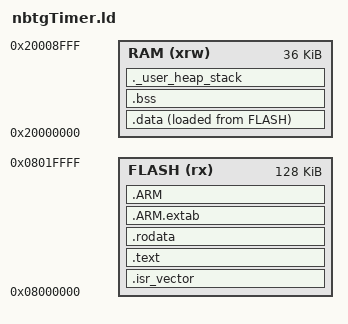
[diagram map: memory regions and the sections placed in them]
/*
******************************************************************************
**

**  File        : LinkerScript.ld
**
**  Author		: STM32CubeMX
**
**  Abstract    : Linker script for STM32G070RBTx series
**                128Kbytes FLASH and 36Kbytes RAM
**
**                Set heap size, stack size and stack location according
**                to application requirements.
**
**                Set memory bank area and size if external memory is used.
**
**  Target      : STMicroelectronics STM32
**
**  Distribution: The file is distributed “as is,” without any warranty
**                of any kind.
**
*****************************************************************************
** @attention
**
** <h2><center>&copy; COPYRIGHT(c) 2019 STMicroelectronics</center></h2>
**
** Redistribution and use in source and binary forms, with or without modification,
** are permitted provided that the following conditions are met:
**   1. Redistributions of source code must retain the above copyright notice,
**      this list of conditions and the following disclaimer.
**   2. Redistributions in binary form must reproduce the above copyright notice,
**      this list of conditions and the following disclaimer in the documentation
**      and/or other materials provided with the distribution.
**   3. Neither the name of STMicroelectronics nor the names of its contributors
**      may be used to endorse or promote products derived from this software
**      without specific prior written permission.
**
** THIS SOFTWARE IS PROVIDED BY THE COPYRIGHT HOLDERS AND CONTRIBUTORS "AS IS"
** AND ANY EXPRESS OR IMPLIED WARRANTIES, INCLUDING, BUT NOT LIMITED TO, THE
** IMPLIED WARRANTIES OF MERCHANTABILITY AND FITNESS FOR A PARTICULAR PURPOSE ARE
** DISCLAIMED. IN NO EVENT SHALL THE COPYRIGHT HOLDER OR CONTRIBUTORS BE LIABLE
** FOR ANY DIRECT, INDIRECT, INCIDENTAL, SPECIAL, EXEMPLARY, OR CONSEQUENTIAL
** DAMAGES (INCLUDING, BUT NOT LIMITED TO, PROCUREMENT OF SUBSTITUTE GOODS OR
** SERVICES; LOSS OF USE, DATA, OR PROFITS; OR BUSINESS INTERRUPTION) HOWEVER
** CAUSED AND ON ANY THEORY OF LIABILITY, WHETHER IN CONTRACT, STRICT LIABILITY,
** OR TORT (INCLUDING NEGLIGENCE OR OTHERWISE) ARISING IN ANY WAY OUT OF THE USE
** OF THIS SOFTWARE, EVEN IF ADVISED OF THE POSSIBILITY OF SUCH DAMAGE.
**
*****************************************************************************
*/

ENTRY(Reset_Handler)

_estack = ORIGIN(RAM) + LENGTH(RAM);    /* end of RAM */

_Min_Heap_Size  = 0x0;
_Min_Stack_Size = 0x400;

MEMORY
{
    RAM (xrw)  : ORIGIN = 0x20000000, LENGTH = 36K
    FLASH (rx) : ORIGIN = 0x08000000, LENGTH = 128K /* 64 pages of 2K each */
}

SECTIONS
{
    /* vectors go to top */
    .isr_vector :
    {
        . = ALIGN(4);
        KEEP(*(.isr_vector))
        . = ALIGN(4);
    } >FLASH

    /* executable code */
    .text :
    {
        . = ALIGN(4);
        *(.text)
        *(.text*)
        *(.glue_7)    /* glue arm to thumb code */
        *(.glue_7t)   /* glue thumb to arm code */
        /* note: no .eh_frame, we don't need it for C, use -fno-asynchronous-unwind-tables */

        KEEP (*(.init))
        KEEP (*(.fini))

        . = ALIGN(4);
        _etext = .;
    } >FLASH

    /* readonly: constants, strings, etc */
    .rodata :
    {
      . = ALIGN(4);
      *(.rodata)
      *(.rodata*)
      . = ALIGN(4);
    } >FLASH

    /* exception table. see AAPCS procedure call standard (EHABI section 7) */
    .ARM.extab :
    {
        *(.ARM.extab* .gnu.linkonce.armextab.*)
    } >FLASH

    .ARM :
    {
        __exidx_start = .;
        *(.ARM.exidx*)    /* exidx contains info needed for stack unwinding */
        __exidx_end = .;
    } >FLASH

    /* provide startup file with location of .data segment in flash; _sdata and _edata are the addresses in RAM */
    _sidata = LOADADDR(.data);

    /* non-const initialized data objects. note AT> FLASH: this means the values are loaded from flash into RAM */
    .data : 
    {
        . = ALIGN(4);
        _sdata = .;        /* create a global symbol at data start */
        *(.data)           /* .data sections */
        *(.data*)          /* .data* sections */

        . = ALIGN(4);
        _edata = .;        /* define a global symbol at data end */
    } >RAM AT> FLASH

    
    /* non-const non-initialized data objects */
    .bss :
    {
        . = ALIGN(4);
        _sbss = .;
        *(.bss)
        *(.bss*)
        *(COMMON)

        . = ALIGN(4);
        _ebss = .;
    } >RAM

    /* User_heap_stack section, used to check that there is enough RAM left */
    ._user_heap_stack :
    {
        . = ALIGN(8);
        _user_heap_base__ = .;
        PROVIDE ( end = . );
        PROVIDE ( _end = . );
        . = . + _Min_Heap_Size;
        . = . + _Min_Stack_Size;
        . = ALIGN(8);
    } >RAM

    /* Remove information from the standard libraries */
    /DISCARD/ :
    {
      libc.a ( * )
      libm.a ( * )
      libgcc.a ( * )
    }

    .ARM.attributes 0 : { *(.ARM.attributes) }
}


